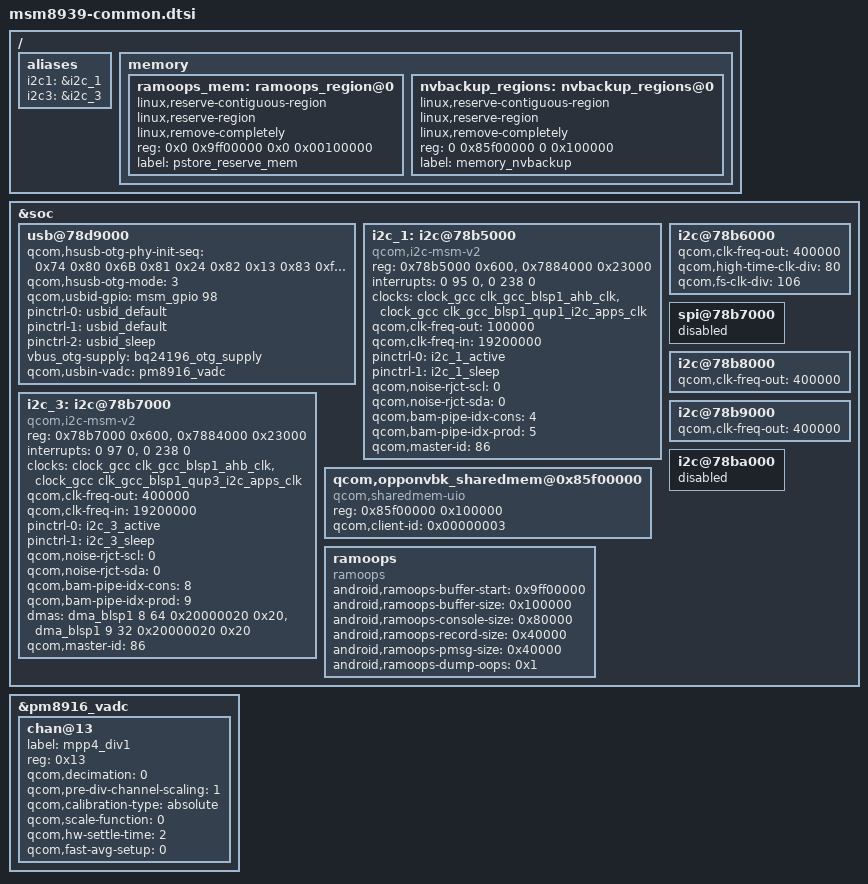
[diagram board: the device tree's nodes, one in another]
/* Copyright (c) 2014-2015, The Linux Foundation. All rights reserved.
 *
 * This program is free software; you can redistribute it and/or modify
 * it under the terms of the GNU General Public License version 2 and
 * only version 2 as published by the Free Software Foundation.
 *
 * This program is distributed in the hope that it will be useful,
 * but WITHOUT ANY WARRANTY; without even the implied warranty of
 * MERCHANTABILITY or FITNESS FOR A PARTICULAR PURPOSE.  See the
 * GNU General Public License for more details.
 */

/ {
	aliases {
		i2c1 = &i2c_1;
		i2c3 = &i2c_3;
	};

	memory {
		ramoops_mem: ramoops_region@0 {
			linux,reserve-contiguous-region;
			linux,reserve-region;
			linux,remove-completely;
			reg = <0x0 0x9ff00000 0x0 0x00100000>;
			label = "pstore_reserve_mem";
		};

		nvbackup_regions: nvbackup_regions@0 {
			linux,reserve-contiguous-region;
			linux,reserve-region;
			linux,remove-completely;
			reg = <0 0x85f00000 0 0x100000>;
			label = "memory_nvbackup";
		};
	};
};

&soc {
	usb@78d9000 {
		qcom,hsusb-otg-phy-init-seq =
			<0x74 0x80 0x6B 0x81 0x24 0x82 0x13 0x83 0xffffffff>;
		qcom,hsusb-otg-mode = <3>;
		qcom,usbid-gpio = <&msm_gpio 98 0>;
		pinctrl-names = "default", "active", "sleep";
		pinctrl-0 = <&usbid_default>;
		pinctrl-1 = <&usbid_default>;
		pinctrl-2 = <&usbid_sleep>;
		vbus_otg-supply = <&bq24196_otg_supply>;
		qcom,usbin-vadc = <&pm8916_vadc>;
	};

	i2c_1: i2c@78b5000 { /* BLSP1 QUP1 */
		compatible = "qcom,i2c-msm-v2";
		#address-cells = <1>;
		#size-cells = <0>;
		reg-names = "qup_phys_addr", "bam_phys_addr";
		reg = <0x78b5000 0x600>,
		      <0x7884000 0x23000>;
		interrupt-names = "qup_irq", "bam_irq";
		interrupts = <0 95 0>, <0 238 0>;
		clocks = <&clock_gcc clk_gcc_blsp1_ahb_clk>,
			 <&clock_gcc clk_gcc_blsp1_qup1_i2c_apps_clk>;
		clock-names = "iface_clk", "core_clk";
		qcom,clk-freq-out = <100000>;
		qcom,clk-freq-in  = <19200000>;
		pinctrl-names = "i2c_active", "i2c_sleep";
		pinctrl-0 = <&i2c_1_active>;
		pinctrl-1 = <&i2c_1_sleep>;
		qcom,noise-rjct-scl = <0>;
		qcom,noise-rjct-sda = <0>;
		qcom,bam-pipe-idx-cons = <4>;
		qcom,bam-pipe-idx-prod = <5>;
		qcom,master-id = <86>;
	};

	i2c@78b6000 { /* BLSP1 QUP2 */
		qcom,clk-freq-out = <400000>;
		qcom,high-time-clk-div = <80>;
		qcom,fs-clk-div = <106>;
	};

	spi@78b7000 { /* BLSP1 QUP3 */
		status = "disabled";
	};

	i2c_3: i2c@78b7000 { /* BLSP1 QUP3 */
		compatible = "qcom,i2c-msm-v2";
		#address-cells = <1>;
		#size-cells = <0>;
		reg-names = "qup_phys_addr", "bam_phys_addr";
		reg = <0x78b7000 0x600>,
		      <0x7884000 0x23000>;
		interrupt-names = "qup_irq", "bam_irq";
		interrupts = <0 97 0>, <0 238 0>;
		clocks = <&clock_gcc clk_gcc_blsp1_ahb_clk>,
			 <&clock_gcc clk_gcc_blsp1_qup3_i2c_apps_clk>;
		clock-names = "iface_clk", "core_clk";
		qcom,clk-freq-out = <400000>;
		qcom,clk-freq-in  = <19200000>;
		pinctrl-names = "i2c_active", "i2c_sleep";
		pinctrl-0 = <&i2c_3_active>;
		pinctrl-1 = <&i2c_3_sleep>;
		qcom,noise-rjct-scl = <0>;
		qcom,noise-rjct-sda = <0>;
		qcom,bam-pipe-idx-cons = <8>;
		qcom,bam-pipe-idx-prod = <9>;
		dmas = <&dma_blsp1 8 64 0x20000020 0x20>,
			<&dma_blsp1 9 32 0x20000020 0x20>;
		dma-names = "tx", "rx";
		qcom,master-id = <86>;
	};

	i2c@78b8000 { /* BLSP1 QUP4 */
		qcom,clk-freq-out = <400000>;
	};

	i2c@78b9000 { /* BLSP1 QUP5 */
		qcom,clk-freq-out = <400000>;
	};

	i2c@78ba000 { /* BLSP1 QUP6 */
		status = "disabled";
	};

	qcom,opponvbk_sharedmem@0x85f00000 {
		compatible = "qcom,sharedmem-uio";
		reg = <0x85f00000 0x100000>;
		reg-names = "opponvbk";
		qcom,client-id = <0x00000003>;
	};

	ramoops {
		compatible = "ramoops";
		status = "okay";

		android,ramoops-buffer-start = <0x9ff00000>;
		android,ramoops-buffer-size = <0x100000>;
		android,ramoops-console-size = <0x80000>;
		android,ramoops-record-size = <0x40000>;
		android,ramoops-pmsg-size = <0x40000>;
		android,ramoops-dump-oops = <0x1>;
	};
};

&pm8916_vadc {
	chan@13 {
		label = "mpp4_div1";
		reg = <0x13>;
		qcom,decimation = <0>;
		qcom,pre-div-channel-scaling = <1>;
		qcom,calibration-type = "absolute";
		qcom,scale-function = <0>;
		qcom,hw-settle-time = <2>;
		qcom,fast-avg-setup = <0>;
	};
};
